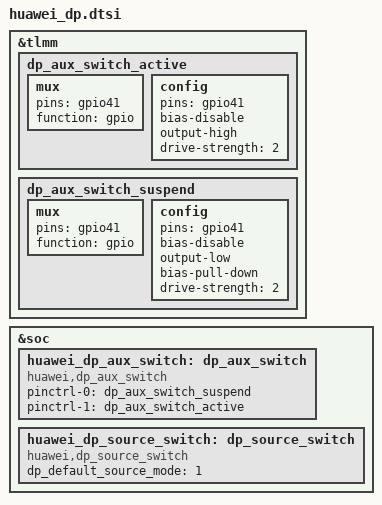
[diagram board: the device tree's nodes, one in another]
&tlmm {
	dp_aux_switch_active: dp_aux_switch_active {
		mux {
			pins = "gpio41";
			function = "gpio";
		};

		config {
			pins = "gpio41";
			bias-disable;
			output-high;
			drive-strength = <2>; /* 2 MA */
		};
	};

	dp_aux_switch_suspend: dp_aux_switch_suspend {
		mux {
			pins = "gpio41";
			function = "gpio";
		};

		config {
			pins = "gpio41";
			bias-disable;
			output-low;
			bias-pull-down; /* PULL DOWN */
			drive-strength = <2>; /* 2 MA */
		};
	};
};

&soc {
	huawei_dp_aux_switch: dp_aux_switch {
		compatible = "huawei,dp_aux_switch";
		pinctrl-names = "default", "aux_enable";
		pinctrl-0 = <&dp_aux_switch_suspend>;
		pinctrl-1 = <&dp_aux_switch_active>;
		status = "ok";
	};

	huawei_dp_source_switch: dp_source_switch {
		compatible = "huawei,dp_source_switch";
		dp_default_source_mode = <1>; /* 0:diff mode 1:same mode */
		status = "ok";
	};
};
